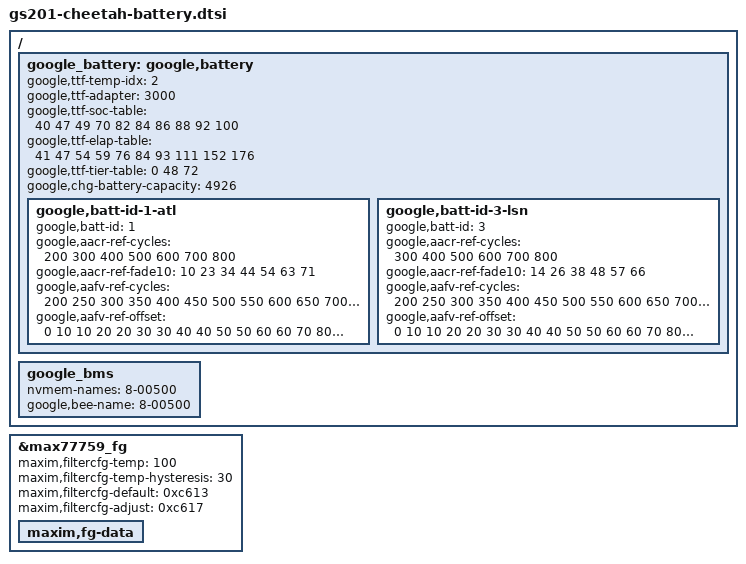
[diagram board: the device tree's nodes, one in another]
// SPDX-License-Identifier: GPL-2.0-only
/*
 * Battery device tree entries specific to raven
 *
 * Copyright 2021 Google,LLC
 *
 */

&google_battery {
	google,chg-battery-capacity = <4926>;
};

&max77759_fg {
	/delete-property/ maxim,force-batt-id;

	maxim,filtercfg-temp = <100>;
	maxim,filtercfg-temp-hysteresis = <30>;
	maxim,filtercfg-default = /bits/ 16 <0xc613>;
	maxim,filtercfg-adjust = /bits/ 16 <0xc617>;

	maxim,fg-data {
		#include "gs201-cheetah-battery-data.dtsi"
	};
};

/ {
	fragment@battery {
		target-path = "/";
		__overlay__ {
			google_battery: google,battery {
				google,ttf-temp-idx= <2>;
				google,ttf-adapter = <3000>;
				google,ttf-soc-table =  <40 47 49 70 82 84 86 88  92  100>;
				google,ttf-elap-table = <41 47 54 59 76 84 93 111 152 176>;
				google,ttf-tier-table = <0 48 72>;

				google,batt-id-1-atl {
					google,batt-id = <1>;
					google,aacr-ref-cycles = <200 300 400 500 600 700 800>;
					google,aacr-ref-fade10 = < 10  23  34  44  54  63  71>;
					google,aafv-ref-cycles = <
						200  250  300  350  400  450  500  550
						600  650  700  750  800  850  900  950
					>;
					google,aafv-ref-offset = <
						  0  10  10  20  20  30  30  40
						 40  50  50  60  60  70  80  90
					>;
				};

				google,batt-id-3-lsn {
					google,batt-id = <3>;
					google,aacr-ref-cycles = <300 400 500 600 700 800>;
					google,aacr-ref-fade10 = < 14  26  38  48  57  66>;
					google,aafv-ref-cycles = <
						200  250  300  350  400  450  500  550
						600  650  700  750  800  850  900  950
					>;
					google,aafv-ref-offset = <
						  0  10  10  20  20  30  30  40
						 40  50  50  60  60  70  80  90
					>;
				};
			};

			google_bms {
				nvmem-names = "8-00500";
				/* pack eeprom is available only with P20+ batteries */
				google,bee-name = "8-00500";
			};
		};
	};
};
